# V32F20x_CM33 register map
File version: 1.0.3
CPU: CM33 r0p4, little endian, MPU, FPU, DSP, 3 interrupt priority bits, 8 SAU regions
Registers are 32-bit, read-write, reset 0x0 unless marked. A register's access mark holds for its fields unless they carry their own. Offsets are from the block's base; [hi:lo] are bit positions; {n}, {i} and the like mark numbered series; 'fields as' and 'values as' point back to an identical list.

## USB_FS — USB_FS Peripheral Interface
Base 0x20280000
Same registers: SEC_USB_FS 0x30280000
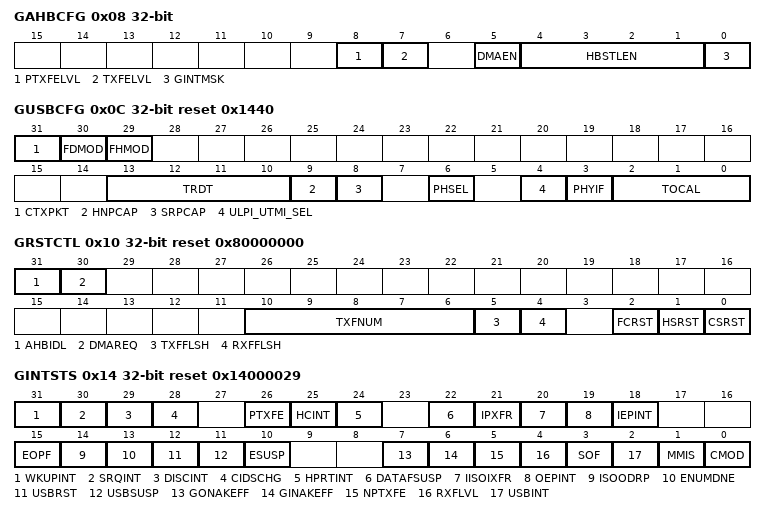
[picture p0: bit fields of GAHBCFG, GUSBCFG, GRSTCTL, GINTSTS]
0x08 GAHBCFG — USB_FS AHB configuration register
  [8] PTXFELVL — Periodic TxFIFO Empty Level
  [7] TXFELVL — Non-Periodic TxFIFO Empty Level
  [5] DMAEN — DMA Enable
  [4:1] HBSTLEN — Burst Length/Type
  [0] GINTMSK — Global Interrupt Mask
0x0C GUSBCFG reset 0x1440 — USB_FS USB configuration register
  [31] CTXPKT — Corrupt Tx packet
  [30] FDMOD — Force Device Mode
  [29] FHMOD — Force Host Mode
  [13:10] TRDT — USB Turnaround Time
  [9] HNPCAP — HNP-Capable
  [8] SRPCAP — SRP-Capable
  [6] PHSEL — USB 2
  [4] ULPI_UTMI_SEL — ULPI or UTMI+ Select
  [3] PHYIF — PHY Interface
  [2:0] TOCAL — FS Timeout Calibration
0x10 GRSTCTL reset 0x80000000 — USB_FS reset register
  [31] AHBIDL — AHB Master Idle
  [30] DMAREQ — DMA Request Signal
  [10:6] TXFNUM — TxFIFO Number
  [5] TXFFLSH — TxFIFO Flush
  [4] RXFFLSH — RxFIFO Flush
  [2] FCRST — Host Frame Counter Reset
  [1] HSRST — PIU FS Dedicated Controller Soft Reset
  [0] CSRST — Core Soft Reset
0x14 GINTSTS reset 0x14000029 — USB_FS core interrupt register
  [31] WKUPINT — Resume Remote Wakeup Detected Interrupt Wakeup Interrupt during Suspend L2 or LPM L1 state
  [30] SRQINT — Session Request/New Session Detected Interrupt
  [29] DISCINT — Disconnect Detected Interrupt Asserted when a device disconnect is detected
  [28] CIDSCHG — Connector ID Status Change
  [26] PTXFE — Periodic TxFIFO Empty
  [25] HCINT — Host Channels Interrupt
  [24] HPRTINT — Host Port Interrupt
  [22] DATAFSUSP — Data Fetch Suspended
  [21] IPXFR — Incomplete Periodic Transfer
  [20] IISOIXFR — Incomplete Isochronous IN Transfer
  [19] OEPINT — OUT Endpoints Interrupt
  [18] IEPINT — IN Endpoints Interrupt
  [15] EOPF — End of Periodic Frame Interrupt
  [14] ISOODRP — Isochronous OUT Packet Dropped Interrupt
  [13] ENUMDNE — Enumeration Done
  [12] USBRST — USB Reset
  [11] USBSUSP — USB Suspend
  [10] ESUSP — Early Suspend
  [7] GONAKEFF — Global OUT NAK Effective
  [6] GINAKEFF — Global IN Non-periodic NAK Effective
  [5] NPTXFE — Non-periodic TxFIFO Empty
  [4] RXFLVL — RxFIFO Non-Empty
  [3] SOF — Start of Frame
  [2] USBINT — USB Interrupt
  [1] MMIS — Mode Mismatch Interrupt
  [0] CMOD — Current Mode of Operation
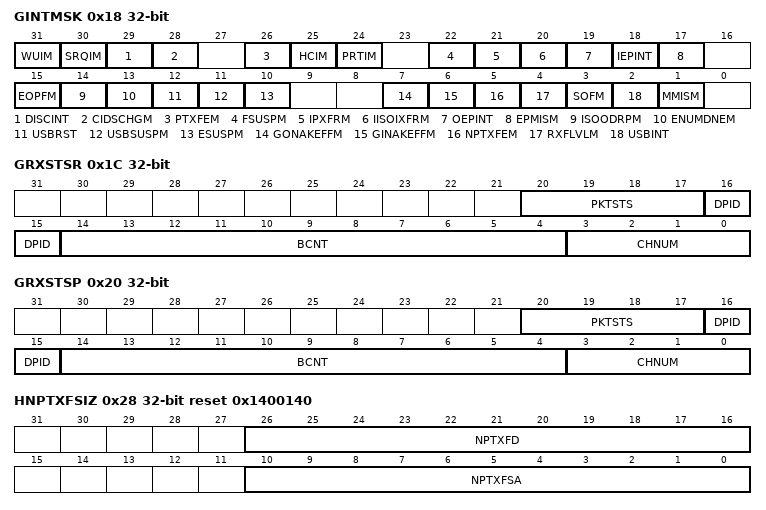
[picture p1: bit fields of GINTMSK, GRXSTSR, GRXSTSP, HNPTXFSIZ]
0x18 GINTMSK — USB_FS interrupt mask register
  [31] WUIM — Resume/Remote Wakeup Detected Interrupt Mask
  [30] SRQIM — Session Request New Session Detected Interrupt Mask
  [29] DISCINT — Disconnect Detected Interrupt Mask
  [28] CIDSCHGM — Connector ID Status Change Mask
  [26] PTXFEM — Periodic TxFIFO Empty Mask
  [25] HCIM — Host Channels Interrupt Mask
  [24] PRTIM — Host Port Interrupt Mask
  [22] FSUSPM — Data Fetch Suspended Mask
  [21] IPXFRM — Incomplete Periodic Transfer Mask
  [20] IISOIXFRM — Incomplete Isochronous IN Transfer Mask
  [19] OEPINT — OUT Endpoints Interrupt Mask
  [18] IEPINT — IN Endpoints Interrupt Mask
  [17] EPMISM — Endpoint Mismatch Interrupt Mask
  [15] EOPFM — End of Periodic Frame Interrupt Mask
  [14] ISOODRPM — Isochronous OUT Packet Dropped Interrupt Mask
  [13] ENUMDNEM — Enumeration Done Mask
  [12] USBRST — USB Reset Mask
  [11] USBSUSPM — USB Suspend Mask
  [10] ESUSPM — Early Suspend Mask
  [7] GONAKEFFM — Global OUT NAK Effective Mask
  [6] GINAKEFFM — Global Non-periodic IN NAK Effective Mask
  [5] NPTXFEM — Non-periodic TxFIFO Empty Mask
  [4] RXFLVLM — Receive FIFO Non-Empty Mask
  [3] SOFM — Start of Frame Mask
  [2] USBINT — USB Interrupt Mask
  [1] MMISM — Mode Mismatch Interrupt Mask
0x1C GRXSTSR — USB_FS Receive status debug read register
  [20:17] PKTSTS — Packet Status indicates the status of the received packet
  [16:15] DPID — Data PID
  [14:4] BCNT — Byte Count
  [3:0] CHNUM — Channel Number
0x20 GRXSTSP — OTG status read and pop registers
  fields as GRXSTSR
0x24 GRXFSIZ reset 0x140 — USB_FS Receive FIFO size register
  [10:0] RXFD — RxFIFO Depth
0x28 HNPTXFSIZ reset 0x1400140 — USB_FS Host non-periodic transmit FIFO size register
  [26:16] NPTXFD — Non-periodic TxFIFO Depth
  [10:0] NPTXFSA — Non-periodic Transmit RAM Start Address
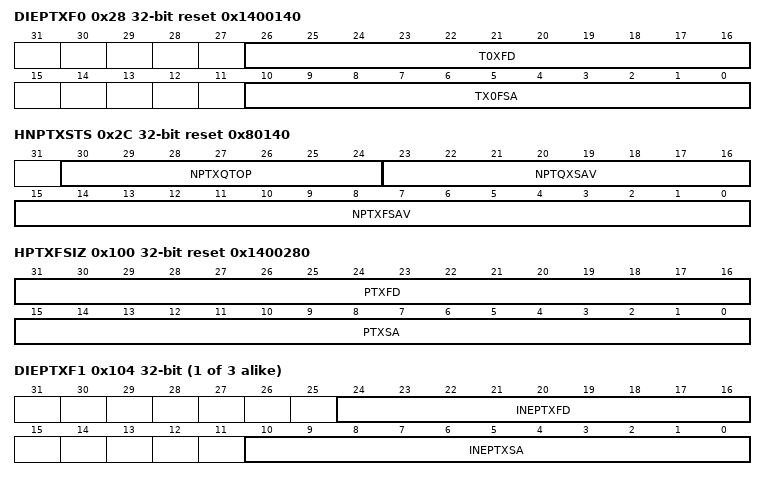
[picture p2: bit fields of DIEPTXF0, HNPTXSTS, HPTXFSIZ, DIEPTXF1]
0x28 DIEPTXF0 reset 0x1400140 (alternate view of HNPTXFSIZ) — Endpoint 0 Transmit FIFO size
  [26:16] T0XFD — IN Endpoint TxFIFO 0 Depth
  [10:0] TX0FSA — IN Endpoint FIFO0 Transmit RAM Start Address
0x2C HNPTXSTS reset 0x80140 — USB_FS non-periodic transmit FIFO/queue status register
  [30:24] NPTXQTOP — Top of the Non-periodic Transmit Request Queue
  [23:16] NPTQXSAV — Non periodic Transmit Request Queue Space Available
  [15:0] NPTXFSAV — Non-periodic TxFIFO Space Avail
0x100 HPTXFSIZ reset 0x1400280 — USB_FS Host periodic transmit FIFO size register
  [31:16] PTXFD — Host Periodic TxFIFO Depth
  [15:0] PTXSA — Host Periodic TxFIFO Start Address
{0x100+4i} DIEPTXF{i} (i=1..3) — USB_FS device IN endpoint transmit FIFO size register
  [24:16] INEPTXFD — IN Endpoint TxFIFO Depth
  [10:0] INEPTXSA — IN Endpoint FIFOn Transmit RAM Start Address
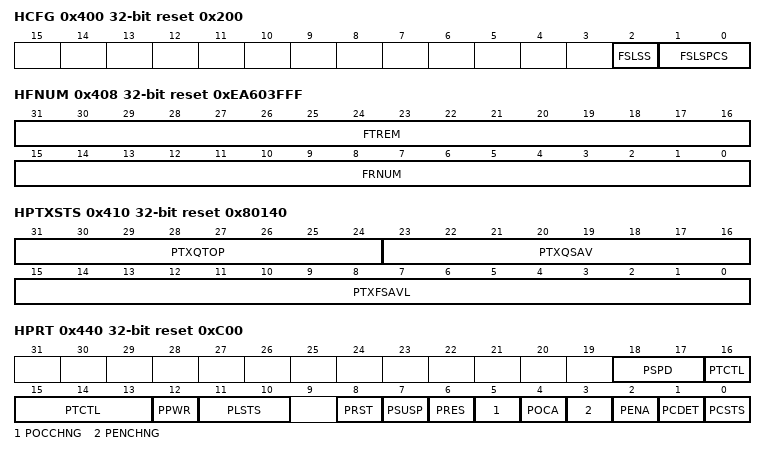
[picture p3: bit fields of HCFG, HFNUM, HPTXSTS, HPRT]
0x400 HCFG reset 0x200 — USB_FS Host configuration register
  [2] FSLSS — FS- and LS-Only Support
  [1:0] FSLSPCS — FS/LS PHY Clock Select
0x404 HFIR reset 0xEA60 — USB_FS Host frame interval register
  [15:0] FRIVL — Frame Interval
0x408 HFNUM reset 0xEA603FFF — USB_FS Host frame number/frame time remaining register
  [31:16] FTREM — Frame Time Remaining
  [15:0] FRNUM — Frame Number
0x410 HPTXSTS reset 0x80140 — USB_FS_Host periodic transmit FIFO/queue status register
  [31:24] PTXQTOP — Top of the Periodic Transmit Request Queue
  [23:16] PTXQSAV — Periodic Transmit Request Queue Space Available
  [15:0] PTXFSAVL — Periodic Transmit Data FIFO Space Available
0x414 HAINT — USB_FS Host all channels interrupt register
  [7:0] HAINT — Channel Interrupt for channel no.
0x418 HAINTMSK — USB_FS Host all channels interrupt mask register
  [7:0] HAINTM — Channel Interrupt Mask
0x440 HPRT reset 0xC00 — USB_FS Host port control and status register
  [18:17] PSPD — Port Speed
  [16:13] PTCTL — Port Test Control
  [12] PPWR — Port Power
  [11:10] PLSTS — Port Line Status
  [8] PRST — Port Reset
  [7] PSUSP — Port Suspend
  [6] PRES — Port Resume
  [5] POCCHNG — Port Overcurrent Change
  [4] POCA — Port Overcurrent Active
  [3] PENCHNG — Port Enable/Disable Change
  [2] PENA — Port Enable
  [1] PCDET — Port Connect Detected
  [0] PCSTS — Port Connect Status
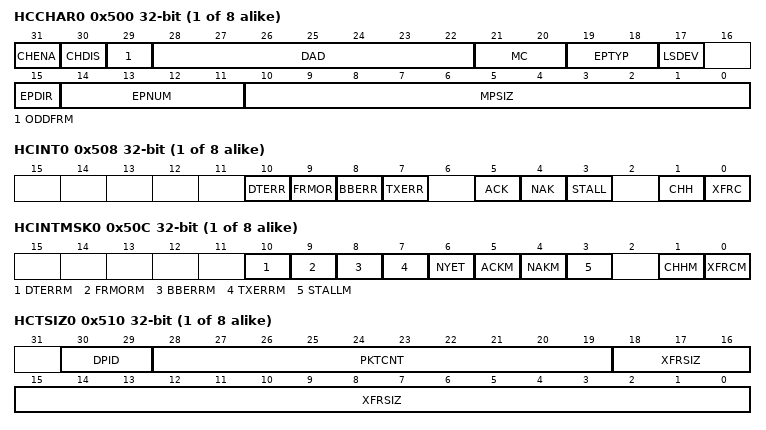
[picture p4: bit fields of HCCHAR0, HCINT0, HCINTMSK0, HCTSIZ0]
{0x500+0x14*i} HCCHAR{i} (i=0..7) — USB_FS Host channel-0 characteristics register
  [31] CHENA — Channel Enable
  [30] CHDIS — Channel Disable
  [29] ODDFRM — Odd Frame
  [28:22] DAD — Device Address
  [21:20] MC — Multi Count (MC) / Error Count (EC)
  [19:18] EPTYP — Endpoint Type
  [17] LSDEV — Low-Speed Device
  [15] EPDIR — Endpoint Direction
  [14:11] EPNUM — Endpoint Number
  [10:0] MPSIZ — Maximum Packet Size
{0x508+0x14*i} HCINT{i} (i=0..7) — USB_FS Host channel-0 interrupt register
  [10] DTERR — Data Toggle Error
  [9] FRMOR — Frame Overrun .
  [8] BBERR — Babble Error
  [7] TXERR — Transaction Error
  [5] ACK — ACK Response Received/Transmitted Interrupt
  [4] NAK — NAK Response Received Interrupt
  [3] STALL — STALL Response Received Interrupt
  [1] CHH — Channel Halted
  [0] XFRC — Transfer Completed
{0x50C+0x14*i} HCINTMSK{i} (i=0..7) — USB_FS Host channel-0 interrupt mask register
  [10] DTERRM — Data Toggle Error Mask
  [9] FRMORM — Frame Overrun Mask
  [8] BBERRM — Babble Error Mask
  [7] TXERRM — Transaction Error Mask
  [6] NYET — NYET Response Received Interrupt Mask
  [5] ACKM — ACK Response Received/Transmitted Interrupt Mask
  [4] NAKM — NAK Response Received Interrupt Mask
  [3] STALLM — STALL Response Received Interrupt Mask
  [1] CHHM — Channel Halted Mask
  [0] XFRCM — Transfer Completed Mask
{0x510+0x14*i} HCTSIZ{i} (i=0..7) — USB_FS Host channel-0 transfer size register
  [30:29] DPID — Data PID
  [28:19] PKTCNT — Packet Count
  [18:0] XFRSIZ — Transfer Size
{0x514+0x14*i} HCDMA{i} (alternate view of HCCHAR{i+1}) (i=0..6) — USB_FS host channel-0 DMA address register
  [31:0] DMAADDR — This field holds the start address in the external memory from which the data for the endpoint must be fetched or to which it must be stored
0x5A0 HCDMA7 — USB_FS host channel-0 DMA address register
  fields as HCDMA0
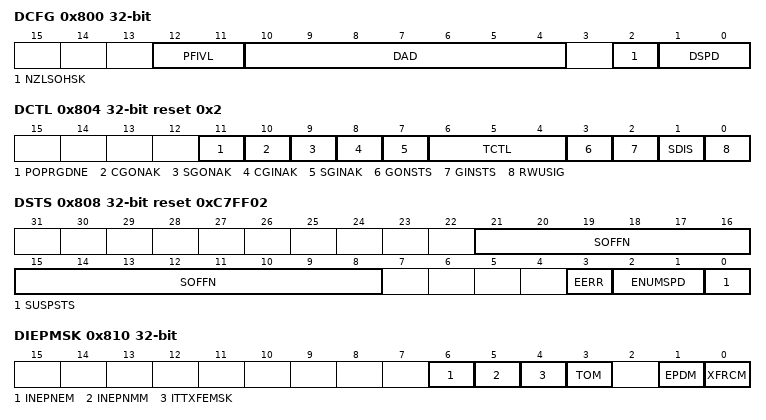
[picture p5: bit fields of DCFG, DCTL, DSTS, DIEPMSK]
0x800 DCFG — USB_FS device configuration register
  [12:11] PFIVL — Periodic Frame Interval
  [10:4] DAD — Device Address
  [2] NZLSOHSK — Non-Zero-Length Status OUT Handshake
  [1:0] DSPD — Device Speed
0x804 DCTL reset 0x2 — USB_FS device control register
  [11] POPRGDNE — Power-On Programming Done
  [10] CGONAK — Clear Global OUT NAK
  [9] SGONAK — Set Global OUT NAK
  [8] CGINAK — Clear Global Non-periodic IN NAK
  [7] SGINAK — Set Global Non-periodic IN NAK
  [6:4] TCTL — Test Control
  [3] GONSTS — Global OUT NAK Status
  [2] GINSTS — Global Non-periodic IN NAK Status
  [1] SDIS — Soft Disconnect
  [0] RWUSIG — Remote Wakeup Signaling
0x808 DSTS reset 0xC7FF02 — USB_FS device status register
  [21:8] SOFFN — Frame or Microframe Number of the Received SOF
  [3] EERR — Erratic Error
  [2:1] ENUMSPD — Enumerated Speed
  [0] SUSPSTS — Suspend Status
0x810 DIEPMSK — USB_FS device IN endpoint common interrupt mask register
  [6] INEPNEM — IN Endpoint NAK Effective Mask
  [5] INEPNMM — IN Token received with EP Mismatch Mask
  [4] ITTXFEMSK — IN Token Received When TxFIFO Empty Mask
  [3] TOM — Timeout Condition Mask Non isochronous endpoints
  [1] EPDM — Endpoint Disabled Interrupt Mask
  [0] XFRCM — Transfer Completed Interrupt Mask
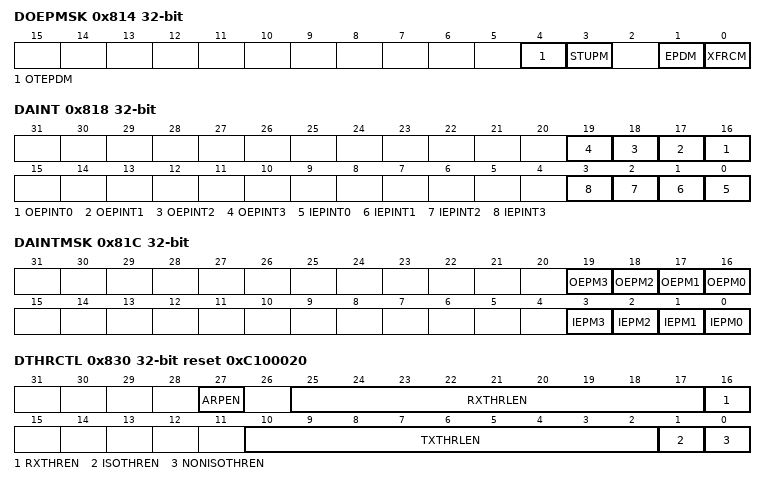
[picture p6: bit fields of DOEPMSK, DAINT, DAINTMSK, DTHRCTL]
0x814 DOEPMSK — USB_FS device OUT endpoint common interrupt mask register
  [4] OTEPDM — OUT Token Received when Endpoint Disabled Mask
  [3] STUPM — SETUP Phase Done Mask
  [1] EPDM — Endpoint Disabled Interrupt Mask
  [0] XFRCM — Transfer Completed Interrupt Mask
0x818 DAINT — USB_FS device all endpoints interrupt register (USB_FS_DAINT)
  [n+16] OEPINT{n} (n=0..3) — OUT Endpoint {n} Interrupt Bit
  [n] IEPINT{n} (n=0..3) — IN Endpoint {n} Interrupt Bit
0x81C DAINTMSK — USB_FS all endpoints interrupt mask register
  [n+16] OEPM{n} (n=0..3) — OUT Endpoint {n} Interrupt mask Bit
  [n] IEPM{n} (n=0..3) — IN Endpoint {n} Interrupt mask Bit
0x830 DTHRCTL reset 0xC100020 — Device Threshold Control Register
  [27] ARPEN — Arbiter Parking Enable
  [25:17] RXTHRLEN — Receive Threshold Length
  [16] RXTHREN — Receive Threshold Enable
  [10:2] TXTHRLEN — Transmit Threshold Length
  [1] ISOTHREN — ISO IN Endpoints Threshold Enable.
  [0] NONISOTHREN — Non-ISO IN Endpoints Threshold Enable.
0x834 DIEPEMPMSK — USB_FS device IN endpoint FIFO empty interrupt mask register
  [15:0] INEPTXFEM — IN EP Tx FIFO Empty Interrupt Mask Bits
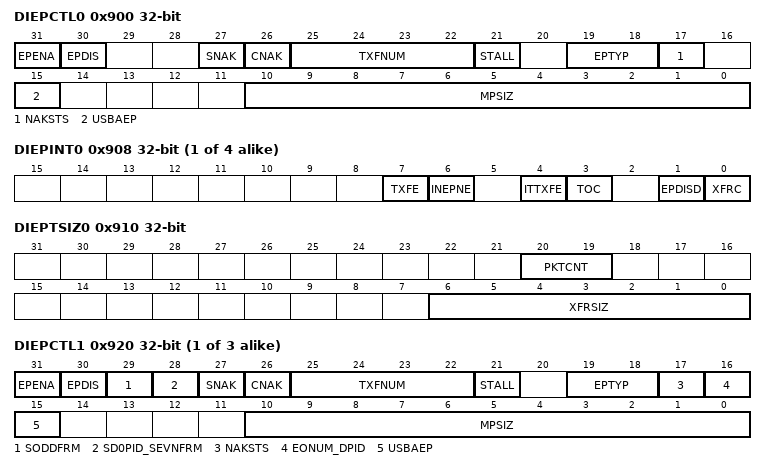
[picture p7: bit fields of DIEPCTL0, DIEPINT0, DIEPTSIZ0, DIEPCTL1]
0x900 DIEPCTL0 — USB_FS device control IN endpoint 0 control register
  [31] EPENA — Endpoint Enable
  [30] EPDIS — Endpoint Disable
  [27] SNAK — Set NAK
  [26] CNAK — Clear NAK
  [25:22] TXFNUM — TxFIFO Number
  [21] STALL — STALL Handshake
  [19:18] EPTYP — Endpoint Type
  [17] NAKSTS — NAK Status
  [15] USBAEP — USB Active Endpoint
  [10:0] MPSIZ — Maximum Packet Size
{0x908+0x14*i} DIEPINT{i} (i=0..3) — USB_FS device endpoint-x interrupt register
  [7] TXFE — Transmit FIFO Empty
  [6] INEPNE — IN Endpoint NAK Effective
  [4] ITTXFE — IN Token Received When TxFIFO is Empty
  [3] TOC — Timeout Condition
  [1] EPDISD — Endpoint Disabled Interrupt
  [0] XFRC — Transfer Completed Interrupt
0x910 DIEPTSIZ0 — USB_FS device IN endpoint 0 transfer size register
  [20:19] PKTCNT — Packet Count
  [6:0] XFRSIZ — Transfer Size
{0x900+0x14*i} DIEPDMA{i} (i=1..3) — Device IN Endpoint i DMA Address Register
  [31:0] DMAADDR — Holds the start address of the external memory for storing or fetching endpoint data
{0x918+0x14*i} DTXFSTS{i} reset 0x140 (i=0..3) — USB_FS device IN endpoint transmit FIFO status register
  [15:0] INEPTFSAV — IN Endpoint TxFIFO Space Avail
{0x90C+0x14*i} DIEPCTL{i} (i=1..3) — OTG device endpoint-x control register
  [31] EPENA — Endpoint Enable
  [30] EPDIS — Endpoint Disable
  [29] SODDFRM — Set DATA1 PID
  [28] SD0PID_SEVNFRM — Set DATA0 PID
  [27] SNAK — Set NAK
  [26] CNAK — Clear NAK
  [25:22] TXFNUM — TxFIFO Number
  [21] STALL — STALL Handshake
  [19:18] EPTYP — Endpoint Type
  [17] NAKSTS — NAK Status
  [16] EONUM_DPID — Endpoint Data PID
  [15] USBAEP — USB Active Endpoint
  [10:0] MPSIZ — Maximum Packet Size
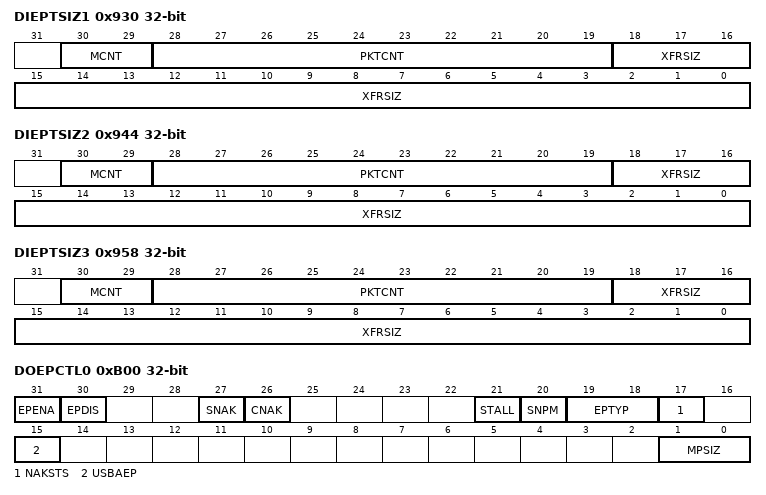
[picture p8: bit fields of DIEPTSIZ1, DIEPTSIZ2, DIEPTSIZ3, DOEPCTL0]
0x930 DIEPTSIZ1 (alternate view of DIEPINT2) — USB_FS device OUT endpoint-x transfer size register
  [30:29] MCNT — Applies to IN endpoints only.
  [28:19] PKTCNT — Packet Count
  [18:0] XFRSIZ — Transfer Size
0x944 DIEPTSIZ2 (alternate view of DIEPINT3) — USB_FS device OUT endpoint-x transfer size register
  fields as DIEPTSIZ1
0x958 DIEPTSIZ3 — USB_FS device OUT endpoint-x transfer size register
  fields as DIEPTSIZ1
0xB00 DOEPCTL0 — USB_FS device control OUT endpoint 0 control register
  [31] EPENA — this bit indicates that the application has allocated the memory to start receiving data from the USB
  [30] EPDIS — Endpoint Disable
  [27] SNAK — Set NAK
  [26] CNAK — Clear NAK
  [21] STALL — STALL Handshake
  [20] SNPM — Snoop mode
  [19:18] EPTYP — Endpoint Type
  [17] NAKSTS — NAK Status
  [15] USBAEP — USB Active Endpoint
  [1:0] MPSIZ — Maximum Packet Size
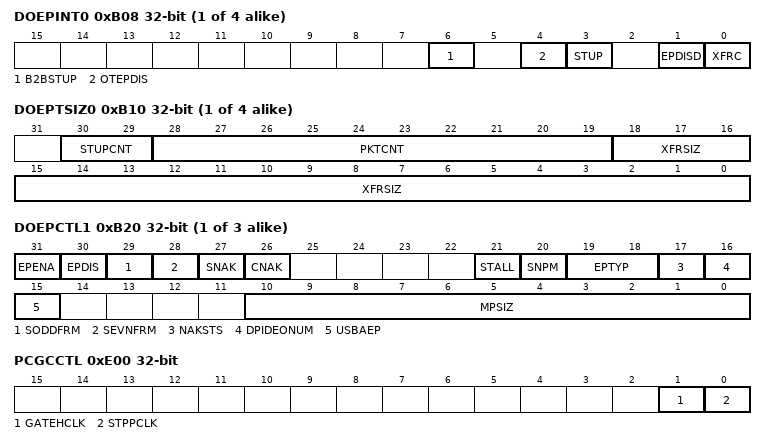
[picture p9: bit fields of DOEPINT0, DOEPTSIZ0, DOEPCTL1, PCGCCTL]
{0xB08+0x14*i} DOEPINT{i} (i=0..3) — USB_FS device endpoint-x interrupt register
  [6] B2BSTUP — Back-to-Back SETUP Packets Received
  [4] OTEPDIS — OUT Token Received When Endpoint Disabled
  [3] STUP — SETUP Phase Done
  [1] EPDISD — Endpoint Disabled Interrupt
  [0] XFRC — Transfer Completed Interrupt
{0xB10+0x14*i} DOEPTSIZ{i} (i=0..3) — USB_FS device OUT endpoint-x transfer size register
  [30:29] STUPCNT — Applies to isochronous OUT endpoints only.
  [28:19] PKTCNT — Packet Count
  [18:0] XFRSIZ — Transfer Size
{0xB00+0x14*i} DOEPDMA{i} (i=1..3) — Device OUT Endpoint i DMA Address Register
  fields as DIEPDMA1
{0xB0C+0x14*i} DOEPCTL{i} (i=1..3) — OTG device endpoint-x control register
  [31] EPENA — Endpoint Enable
  [30] EPDIS — Endpoint Disable
  [29] SODDFRM — Set DATA1 PID
  [28] SEVNFRM — Set DATA0 PID
  [27] SNAK — Set NAK
  [26] CNAK — Clear NAK
  [21] STALL — STALL Handshake
  [20] SNPM — Snoop mode
  [19:18] EPTYP — Endpoint Type
  [17] NAKSTS — NAK Status
  [16] DPIDEONUM — Endpoint Data PID
  [15] USBAEP — USB Active Endpoint
  [10:0] MPSIZ — Maximum Packet Size
0xE00 PCGCCTL — Power and clock gating control register
  [1] GATEHCLK
  [0] STPPCLK — Stop Pclk
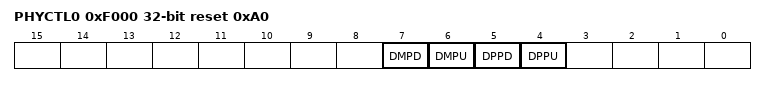
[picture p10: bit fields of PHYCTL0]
0xF000 PHYCTL0 reset 0xA0 — PHY control register 0
  [7] DMPD — Pull-down resistor in DM enable pin
  [6] DMPU — Pull-up resistor in DM enable pin
  [5] DPPD — Pull-down resistor inDP enable pin
  [4] DPPU — Pull-up resistor inDP enable pin
